# STM32L412 register map
File version: 1.9
CPU: CM4 r0p1, little endian, MPU, FPU, 4 interrupt priority bits
Registers are 32-bit, read-write, reset 0x0 unless marked. A register's access mark holds for its fields unless they carry their own. Offsets are from the block's base; [hi:lo] are bit positions; {n}, {i} and the like mark numbered series; 'fields as' and 'values as' point back to an identical list.

## EXTI — External interrupt/event controller
Base 0x40010400
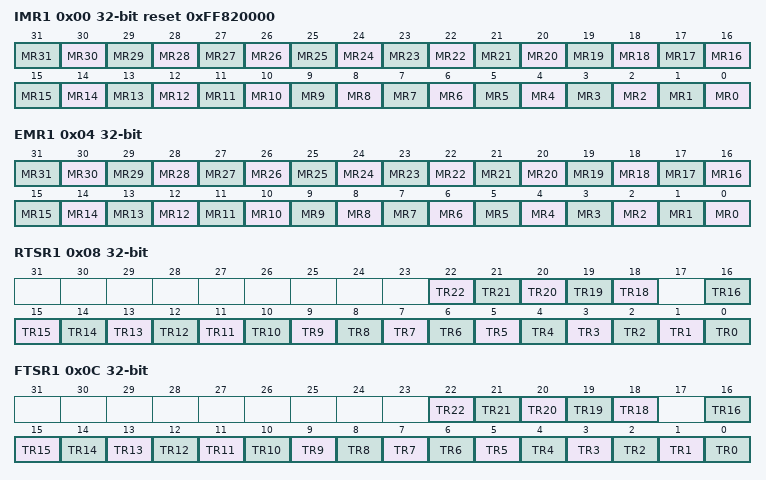
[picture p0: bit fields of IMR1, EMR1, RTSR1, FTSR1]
0x00 IMR1 reset 0xFF820000 — Interrupt mask register
  [all] fields
    0=Masked (Interrupt request line is masked); 1=Unmasked (Interrupt request line is unmasked)
  [n] MR{n} (n=0..31) — Interrupt Mask on line {n}
0x04 EMR1 — Event mask register
  [all] fields
    0=Masked (Event request line is masked); 1=Unmasked (Event request line is unmasked)
  [n] MR{n} (n=0..31) — Event Mask on line {n}
0x08 RTSR1 — Rising Trigger selection register
  [all] fields
    0=Disabled (Rising edge trigger is disabled); 1=Enabled (Rising edge trigger is enabled)
  [n] TR{n} (n=18..22) — Rising trigger event configuration of line {n}
  [n] TR{n} (n=0..16) — Rising trigger event configuration of line {n}
0x0C FTSR1 — Falling Trigger selection register
  [all] fields
    0=Disabled (Falling edge trigger is disabled); 1=Enabled (Falling edge trigger is enabled)
  [n] TR{n} (n=18..22) — Falling trigger event configuration of line {n}
  [n] TR{n} (n=0..16) — Falling trigger event configuration of line {n}
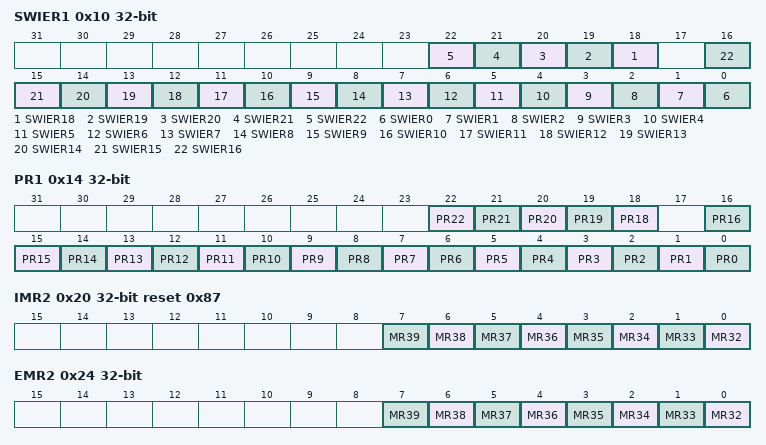
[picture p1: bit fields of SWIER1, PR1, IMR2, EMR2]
0x10 SWIER1 — Software interrupt event register
  [all] fields
    on write: 1=Pend (Generates an interrupt request)
  [n] SWIER{n} (n=18..22) — Software Interrupt on line {n}
  [n] SWIER{n} (n=0..16) — Software Interrupt on line {n}
0x14 PR1 — Pending register
  [all] fields
    on read: 0=NotPending (No trigger request occurred); 1=Pending (Selected trigger request occurred) | on write: 1=Clears pending bit
  [n] PR{n} write-1-clears (n=18..22) — Pending bit {n}
  [n] PR{n} write-1-clears (n=0..16) — Pending bit {n}
0x20 IMR2 reset 0x87 — Interrupt mask register
  [all] fields
    values as the fields of IMR1
  [n-32] MR{n} (n=32..39) — Interrupt Mask on external/internal line {n}
0x24 EMR2 — Event mask register
  [all] fields
    values as the fields of EMR1
  [n-32] MR{n} (n=32..39) — Event mask on external/internal line {n}
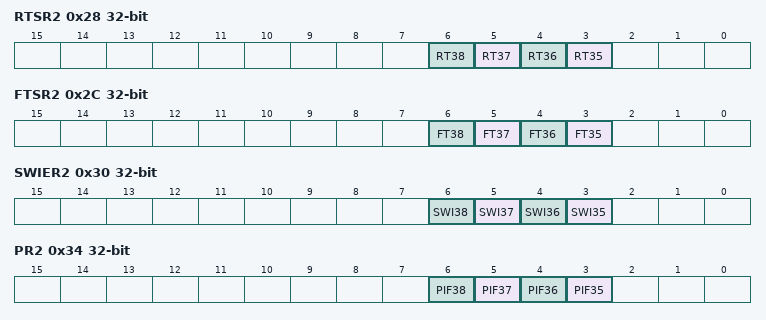
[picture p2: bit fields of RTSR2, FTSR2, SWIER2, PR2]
0x28 RTSR2 — Rising Trigger selection register
  [all] fields
    values as the fields of RTSR1
  [n-32] RT{n} (n=35..38) — Rising trigger event configuration bit of line {n}
0x2C FTSR2 — Falling Trigger selection register
  [all] fields
    values as the fields of FTSR1
  [n-32] FT{n} (n=35..38) — Falling trigger event configuration bit of line {n}
0x30 SWIER2 — Software interrupt event register
  [all] fields
    on write: 1=Pend (Generates an interrupt request)
  [n-32] SWI{n} (n=35..38) — Software interrupt on line {n}
0x34 PR2 — Pending register
  [all] fields
    values as the fields of PR1
  [n-32] PIF{n} write-1-clears (n=35..38) — Pending interrupt flag on line {n}

## FIREWALL
Base 0x40011C00
0x00 CSSA — Code segment start address
  [23:8] ADD — code segment start address
0x04 CSL — Code segment length
  [21:8] LENG — code segment length
0x08 NVDSSA — Non-volatile data segment start address
  [23:8] ADD
0x0C NVDSL — Non-volatile data segment length
  [21:8] LENG
0x10 VDSSA — Volatile data segment start address
  [15:6] ADD
0x14 VDSL — Volatile data segment length
  [15:6] LENG — Non-volatile data segment length
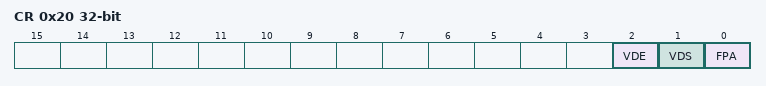
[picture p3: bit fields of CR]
0x20 CR — Configuration register
  [2] VDE — Volatile data execution
    on read: 0=NotExecutable (Volatile data segment cannot be executed if VDS = 0); 1=Executable (Volatile data segment is declared executable whatever VDS bit value) | on write: 0=Resets volatile data execution bit
  [1] VDS — Volatile data shared
    on read: 0=NotShared (Volatile data segment is not shared and cannot be hit by a non protected executable code when the Firewall is closed); 1=Shared (Volatile data segment is shared with non protected application code) | on write: 0=Resets volatile data shared bit
  [0] FPA — Firewall pre alarm
    on write: 0=PreArmReset (Any code executed outside the protected segment when the Firewall is opened will generate a system reset); 1=PreArmSet (Any code executed outside the protected segment will close the Firewall)
